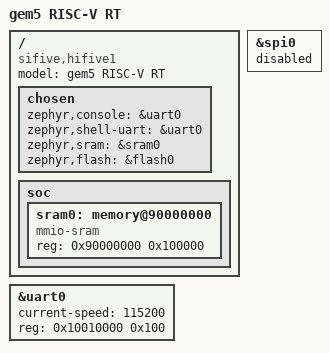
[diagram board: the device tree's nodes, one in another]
/dts-v1/;
#include <sifive/riscv32-fe310.dtsi>

/ {
	model = "gem5 RISC-V RT";
	compatible = "sifive,hifive1";

	chosen {
		zephyr,console = &uart0;
		zephyr,shell-uart = &uart0;
		zephyr,sram = &sram0;
		zephyr,flash = &flash0;
	};

    soc {
        sram0: memory@90000000 {
            compatible = "mmio-sram";
            reg = <0x90000000 0x100000>;
        };
    };
};

&uart0 {
	status = "okay";
	current-speed = <115200>;
    reg = <0x10010000 0x100>;
};

&spi0 {
    status = "disabled";
};
